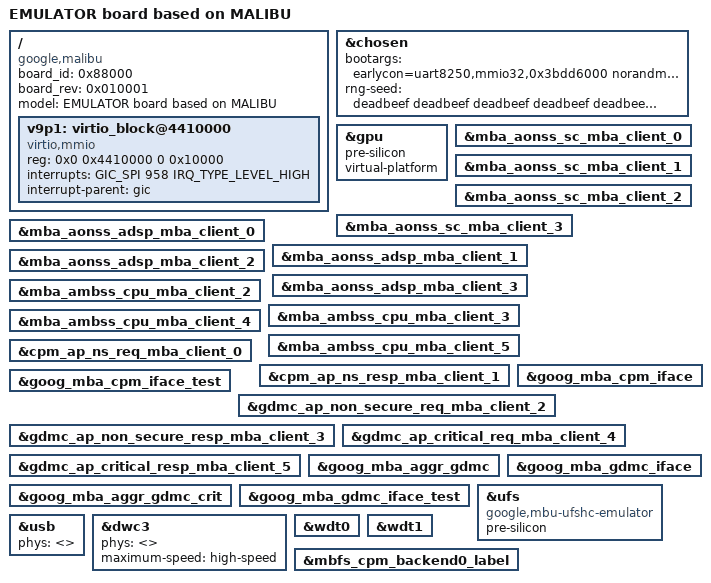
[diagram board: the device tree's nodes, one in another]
// SPDX-License-Identifier: GPL-2.0-only
/*
 * Spacecraft device tree source
 *
 * Copyright 2024 Google LLC
 */

/dts-v1/;
/plugin/;

#include <dt-bindings/interrupt-controller/arm-gic.h>
#include "malibu-spacecraft-gem5-gia.dtsi"
#include "malibu-spacecraft-pinctrl.dtsi"
#include "google-base/platform/malibu-platform-buttons.dtsi"

/ {
	board_id = <0x88000>;
	board_rev = <0x010001>;
	fragment@boardbase {
		target-path = "/";
		__overlay__ {
			model = "EMULATOR board based on MALIBU";
			compatible = "google,malibu", "google,malibu-emulator";
		};
	};

	fragment@virt_dp {
		target-path = "/";
		__overlay__ {
			#address-cells = <2>;
			#size-cells = <2>;
			v9p1: virtio_block@4410000 {
				compatible = "virtio,mmio";
				reg = <0x0 0x4410000 0 0x10000>;
				interrupts = <GIC_SPI 958 IRQ_TYPE_LEVEL_HIGH>;
				interrupt-parent = <&gic>;
			};
		};
	};
};

&chosen {
	bootargs = "earlycon=uart8250,mmio32,0x3bdd6000 norandmaps ro androidboot.force_normal_boot=1 loglevel=8 init=/init console=ttyS0,12500000n8 google_8250.nr_uarts=4 androidboot.boot_devices=3c2d0000.ufs printk.devkmsg=on firmware_class.path=/vendor/firmware fw_devlink=rpm androidboot.hardware.platform=gem5 androidboot.selinux=permissive pvrsrvkm.FabricCoherencyOverride=0 arm64.nomte cma=37M androidboot.apex.early_adbd=1 log_buf_len=4M";
	/* hardcode rng seed for gem5 */
	rng-seed = "deadbeef deadbeef deadbeef deadbeef deadbeef deadbeef /
		    deadbeef deadbeef deadbeef deadbeef deadbeef deadbeef /
		    deadbeef deadbeef deadbeef deadbeef deadbeef deadbeef";
};

&gpu {
	pre-silicon;
	virtual-platform;
};

&mba_aonss_sc_mba_client_0 {
        status = "okay";
};

&mba_aonss_sc_mba_client_1 {
        status = "okay";
};

&mba_aonss_sc_mba_client_2 {
        status = "okay";
};

&mba_aonss_sc_mba_client_3 {
        status = "okay";
};

&mba_aonss_adsp_mba_client_0 {
        status = "okay";
};

&mba_aonss_adsp_mba_client_1 {
        status = "okay";
};

&mba_aonss_adsp_mba_client_2 {
        status = "okay";
};

&mba_aonss_adsp_mba_client_3 {
        status = "okay";
};

&mba_ambss_cpu_mba_client_2 {
        status = "okay";
};

&mba_ambss_cpu_mba_client_3 {
        status = "okay";
};

&mba_ambss_cpu_mba_client_4 {
        status = "okay";
};

&mba_ambss_cpu_mba_client_5 {
        status = "okay";
};

&cpm_ap_ns_req_mba_client_0 {
        status = "okay";
};

&cpm_ap_ns_resp_mba_client_1 {
        status = "okay";
};

&goog_mba_cpm_iface {
        status = "okay";
};

&goog_mba_cpm_iface_test {
        status = "okay";
};

&gdmc_ap_non_secure_req_mba_client_2 {
        status = "okay";
};

&gdmc_ap_non_secure_resp_mba_client_3 {
        status = "okay";
};

&gdmc_ap_critical_req_mba_client_4 {
        status = "okay";
};

&gdmc_ap_critical_resp_mba_client_5 {
        status = "okay";
};

&goog_mba_aggr_gdmc {
        status = "okay";
};

&goog_mba_aggr_gdmc_crit {
        status = "okay";
};

&goog_mba_gdmc_iface {
        status = "okay";
};

&goog_mba_gdmc_iface_test {
        status = "okay";
};

&ufs {
	compatible = "google,mbu-ufshc-emulator";
	pre-silicon;
};

&usb {
	phys = <>;
};

&dwc3 {
	phys = <>;
	maximum-speed = "high-speed";
};

&wdt0 {
	status = "okay";
};

&wdt1 {
	status = "okay";
};

&mbfs_cpm_backend0_label {
	status = "okay";
};
